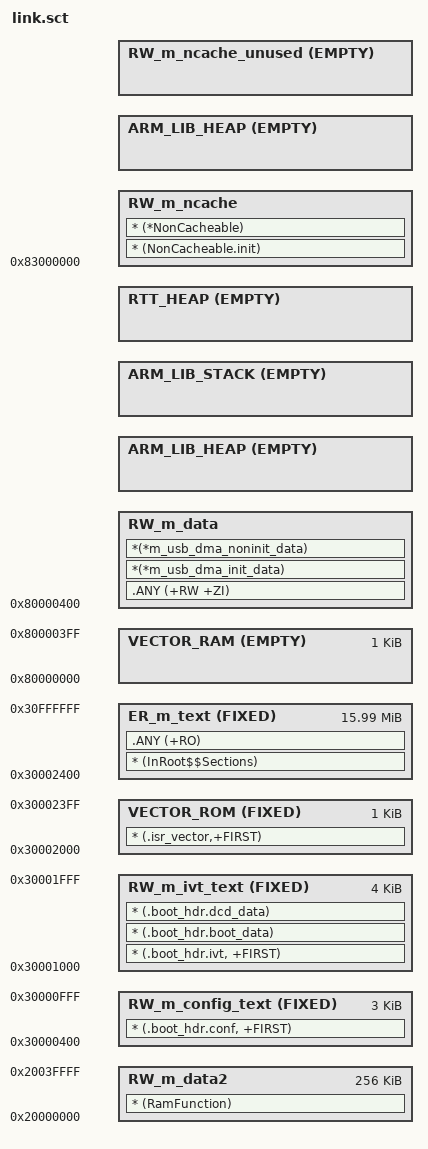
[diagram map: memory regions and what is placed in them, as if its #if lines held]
#!armclang --target=arm-arm-none-eabi -mcpu=cortex-m7 -E -x c
/*
** ###################################################################
**     Processors:          MIMXRT1176AVM8A_cm7
**                          MIMXRT1176CVM8A_cm7
**                          MIMXRT1176DVMAA_cm7
**
**     Compiler:            Keil ARM C/C++ Compiler
**     Reference manual:    IMXRT1170RM, Rev E, 12/2019
**     Version:             rev. 0.1, 2018-03-05
**     Build:               b200828
**
**     Abstract:
**         Linker file for the Keil ARM C/C++ Compiler
**
**     Copyright 2016 Freescale Semiconductor, Inc.
**     Copyright 2016-2020 NXP
**     All rights reserved.
**
**     SPDX-License-Identifier: BSD-3-Clause
**
**     http:                 www.nxp.com
**     mail:                 support@nxp.com
**
** ###################################################################
*/

#if (defined(__ram_vector_table__))
  #define __ram_vector_table_size__    0x00000400
#else
  #define __ram_vector_table_size__    0x00000000
#endif

#define m_flash_config_start           0x30000400
#define m_flash_config_size            0x00000C00

#define m_ivt_start                    0x30001000
#define m_ivt_size                     0x00001000

#define m_interrupts_start             0x30002000
#define m_interrupts_size              0x00000400

#define m_text_start                   0x30002400
#define m_text_size                    0x00FFDC00

#define m_interrupts_ram_start         0x80000000
#define m_interrupts_ram_size          __ram_vector_table_size__

#define  m_data_start                  (m_interrupts_ram_start + m_interrupts_ram_size)
#define  m_data_size                   (0x03000000 - m_interrupts_ram_size)

#define m_ncache_start                 0x83000000
#define m_ncache_size                  0x01000000

#define m_data2_start                  0x20000000
#define m_data2_size                   0x00040000

#define m_data3_start                  0x202C0000
#define m_data3_size                   0x00080000

/* Sizes */
#if (defined(__stack_size__))
  #define Stack_Size                   __stack_size__
#else
  #define Stack_Size                   0x0400
#endif

#if (defined(__heap_size__))
  #define Heap_Size                    __heap_size__
#else
  #define Heap_Size                    0x0400
#endif
#include "../../rtconfig.h"
#define RTT_HEAP_SIZE (m_data_size-ImageLength(RW_m_data)-ImageLength(ARM_LIB_HEAP)-ImageLength(ARM_LIB_STACK))

#if defined(XIP_BOOT_HEADER_ENABLE) && (XIP_BOOT_HEADER_ENABLE == 1)
LR_m_text m_flash_config_start m_text_start+m_text_size-m_flash_config_start {   ; load region size_region
  RW_m_config_text m_flash_config_start FIXED m_flash_config_size { ; load address = execution address
    * (.boot_hdr.conf, +FIRST)
  }

  RW_m_ivt_text m_ivt_start FIXED m_ivt_size { ; load address = execution address
    * (.boot_hdr.ivt, +FIRST)
    * (.boot_hdr.boot_data)
    * (.boot_hdr.dcd_data)
  }
#else
LR_m_text m_interrupts_start m_text_start+m_text_size-m_interrupts_start {   ; load region size_region
#endif
  VECTOR_ROM m_interrupts_start FIXED m_interrupts_size { ; load address = execution address
    * (.isr_vector,+FIRST)
  }
  ER_m_text m_text_start FIXED m_text_size { ; load address = execution address
    * (InRoot$$Sections)
    .ANY (+RO)
  }
#if (defined(__ram_vector_table__))
  VECTOR_RAM m_interrupts_ram_start EMPTY m_interrupts_ram_size {
  }
#else
  VECTOR_RAM m_interrupts_start EMPTY 0 {
  }
#endif
  RW_m_data2 m_data2_start m_data2_size {
    * (RamFunction)
  }
#if (defined(__heap_noncacheable__))
  RW_m_data m_data_start m_data_size-Stack_Size { ; RW data
#else
  RW_m_data m_data_start m_data_size-Stack_Size-Heap_Size { ; RW data
#endif
    .ANY (+RW +ZI)
    *(*m_usb_dma_init_data)
    *(*m_usb_dma_noninit_data)
  }
#if (!defined(__heap_noncacheable__))
  ARM_LIB_HEAP +0 EMPTY Heap_Size {    ; Heap region growing up
  }
#endif
 ; ARM_LIB_STACK m_data_start+m_data_size EMPTY -Stack_Size { ; Stack region growing down
 ; }
    ARM_LIB_STACK +0 EMPTY Stack_Size{} ; Stack region growing down
    RTT_HEAP +0 EMPTY RTT_HEAP_SIZE{}
#if (defined(__heap_noncacheable__))
  RW_m_ncache m_ncache_start m_ncache_size - Heap_Size { ; ncache RW data
#else
  RW_m_ncache m_ncache_start m_ncache_size { ; ncache RW data
#endif
    * (NonCacheable.init)
    * (*NonCacheable)
  }
#if (defined(__heap_noncacheable__))
  ARM_LIB_HEAP +0 EMPTY Heap_Size {    ; Heap region growing up
  }
  RW_m_ncache_unused +0 EMPTY m_ncache_size-ImageLength(RW_m_ncache)-Heap_Size { ; Empty region added for MPU configuration
#else
  RW_m_ncache_unused +0 EMPTY m_ncache_size-ImageLength(RW_m_ncache) { ; Empty region added for MPU configuration
#endif
  }
}
